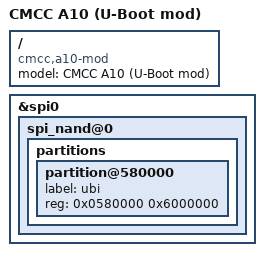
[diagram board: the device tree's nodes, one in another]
// SPDX-License-Identifier: GPL-2.0-or-later OR MIT

/dts-v1/;
#include "mt7981b-cmcc-a10.dts"

/ {
	model = "CMCC A10 (U-Boot mod)";
	compatible = "cmcc,a10-mod", "mediatek,mt7981";
};

&spi0 {
	spi_nand@0 {
		partitions {
			partition@580000 {
				label = "ubi";
				reg = <0x0580000 0x6000000>;
			};

			/delete-node/ partition@4580000;
		};
	};
};
